VERSION "0.1"

NS_ :

BS_:

BU_: VCU ACTUATOR TESTER

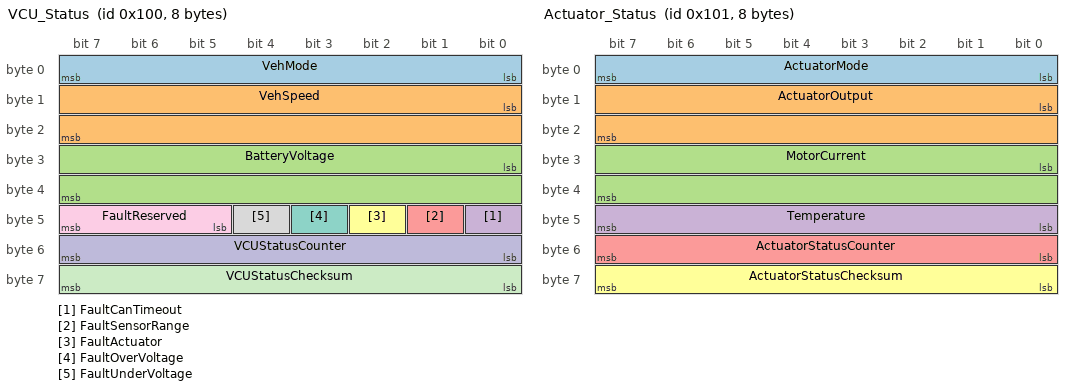
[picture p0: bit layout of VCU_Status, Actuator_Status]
BO_ 256 VCU_Status: 8 VCU
 SG_ VehMode : 0|8@1+ (1,0) [0|3] "" ACTUATOR,TESTER
 SG_ VehSpeed : 8|16@1+ (0.1,0) [0|6553.5] "km/h" ACTUATOR,TESTER
 SG_ BatteryVoltage : 24|16@1+ (0.01,0) [0|655.35] "V" ACTUATOR,TESTER
 SG_ FaultCanTimeout : 40|1@1+ (1,0) [0|1] "" ACTUATOR,TESTER
 SG_ FaultSensorRange : 41|1@1+ (1,0) [0|1] "" ACTUATOR,TESTER
 SG_ FaultActuator : 42|1@1+ (1,0) [0|1] "" ACTUATOR,TESTER
 SG_ FaultOverVoltage : 43|1@1+ (1,0) [0|1] "" ACTUATOR,TESTER
 SG_ FaultUnderVoltage : 44|1@1+ (1,0) [0|1] "" ACTUATOR,TESTER
 SG_ FaultReserved : 45|3@1+ (1,0) [0|7] "" ACTUATOR,TESTER
 SG_ VCUStatusCounter : 48|8@1+ (1,0) [0|255] "" ACTUATOR,TESTER
 SG_ VCUStatusChecksum : 56|8@1+ (1,0) [0|255] "" ACTUATOR,TESTER

BO_ 257 Actuator_Status: 8 ACTUATOR
 SG_ ActuatorMode : 0|8@1+ (1,0) [0|3] "" VCU,TESTER
 SG_ ActuatorOutput : 8|16@1+ (0.1,0) [0|100] "%" VCU,TESTER
 SG_ MotorCurrent : 24|16@1+ (0.01,0) [0|655.35] "A" VCU,TESTER
 SG_ Temperature : 40|8@1+ (1,-40) [-40|215] "degC" VCU,TESTER
 SG_ ActuatorStatusCounter : 48|8@1+ (1,0) [0|255] "" VCU,TESTER
 SG_ ActuatorStatusChecksum : 56|8@1+ (1,0) [0|255] "" VCU,TESTER

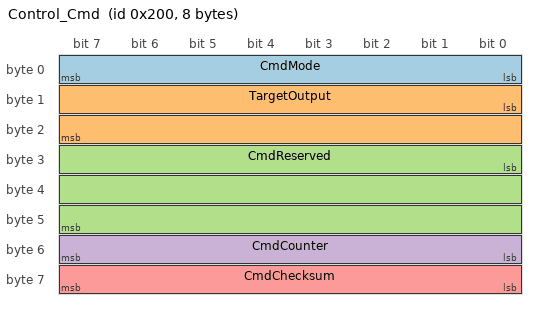
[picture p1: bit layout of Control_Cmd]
BO_ 512 Control_Cmd: 8 VCU
 SG_ CmdMode : 0|8@1+ (1,0) [0|3] "" ACTUATOR,TESTER
 SG_ TargetOutput : 8|16@1+ (0.1,0) [0|100] "%" ACTUATOR,TESTER
 SG_ CmdReserved : 24|24@1+ (1,0) [0|16777215] "" ACTUATOR,TESTER
 SG_ CmdCounter : 48|8@1+ (1,0) [0|255] "" ACTUATOR,TESTER
 SG_ CmdChecksum : 56|8@1+ (1,0) [0|255] "" ACTUATOR,TESTER

CM_ BO_ 256 "VCU status message, 20 ms, rolling counter and CRC-8";
CM_ BO_ 257 "Actuator status message, 50 ms, rolling counter and CRC-8";
CM_ BO_ 512 "Control command, 20 ms, rolling counter and CRC-8";
CM_ SG_ 256 VehSpeed "Vehicle speed, factor 0.1 km/h";
CM_ SG_ 256 BatteryVoltage "Battery voltage, factor 0.01 V";
CM_ SG_ 257 Temperature "Actuator temperature, offset -40 degC";
CM_ SG_ 512 CmdReserved "Reserved for future use, sender writes 0";

BA_DEF_ BO_ "GenMsgCycleTime" INT 0 65535;
BA_DEF_DEF_ "GenMsgCycleTime" 0;
BA_ "GenMsgCycleTime" BO_ 256 20;
BA_ "GenMsgCycleTime" BO_ 257 50;
BA_ "GenMsgCycleTime" BO_ 512 20;

VAL_ 256 VehMode 0 "OFF" 1 "STANDBY" 2 "RUN" 3 "FAULT";
VAL_ 257 ActuatorMode 0 "OFF" 1 "STANDBY" 2 "RUN" 3 "FAULT";
VAL_ 512 CmdMode 0 "OFF" 1 "STANDBY" 2 "RUN" 3 "FAULT";

CM_ "CAN matrix v0.1 - frozen on 2026-10-01";
